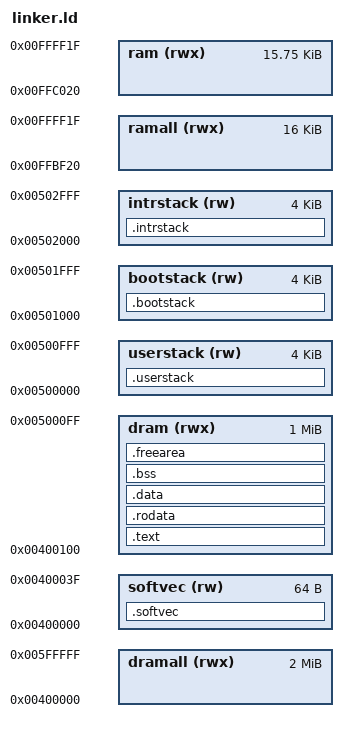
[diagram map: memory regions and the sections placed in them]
/* OUTPUT_FORMAT("elf32-h8300") */
OUTPUT_ARCH(h8300h)
ENTRY("_start")

/*********************************************************************************
	CPUアドレスサイズ 16MB
	割り込みベクタ	0x000000 -> 0x0000FF (256 Bytes)
	内蔵ROM			0x000100 -> 0x07FFFF (512 KB)
	Reserve			0x080000 -> 0xFFBF1F ( )
	内蔵RAM			0xFFBF20 -> 0xFFFF1F (16 KB)
	内蔵I/Oレジスタ	0xFFFF20 -> 0xFFFFE9 (208 bytes)
	Reserve			0xFFFFF0 -> 0xFFFFFF

	PA = Physical Address	物理アドレス
	VA = Vitual Address		論理アドレス

（１）リセット処理 ベクタ番号0 H'0000〜H'0003
RES端子がLowで発生。事実上最も優先順位が高い例外処理です。

（２）トラップ処理 ベクタ番号8〜11
命令語の中に TRAPA という命令が有り、複数のプログラムがあたかも同時に処理されている様な動きを見せます。マルチタスキングシステムでは必須の機能です。ソフトウエア割込とも呼ばれています。４個のTRAPAがあり、レベルを持たせたソフトウエア割込が実現できます。

（３）外部割込 NMI（ノンマスカラブルインタラプト） ベクタ番号７ マスク（阻止）できない外部割込です。
（４）外部割込 IRQ（インタラプトリクエスト） ベクタ番号12〜17 プログラムによってマスク（阻止）したり解除できる割込です。

（５）内部割込 ベクタ番号20〜60 IRQと似ていますが、発生事象がH8チップ内に内蔵する専用機能から発生するものです。その詳細はデーターシートをお読み下さい。

*********************************************************************************/

/*********************************************************************************
	各メモリ領域の定義
**********************************************************************************/
MEMORY
{
	/******************************************************************************
		コロンの前は、定義するメモリ領域の名称。
		ORIGINは、定義するメモリ領域の先頭アドレス。
		LENGTHは、定義するメモリ領域のサイズ。
		カッコ内のrwxはもちろん、読み、書き、実行の可否。
	******************************************************************************/
	/* 「o」はORIGIN、「l」はLENGTH */
	/* ELFヘッダのためにDRAMの先頭256バイト予約 */
	dramall(rwx)	: o = 0x400000, l = 0x200000	/* DRAM領域全体(2MB) */
	dram(rwx)		: o = 0x400100, l = 0x100000
	ramall(rwx)		: o = 0xFFBF20, l = 0x004000	/* RAM領域全体(16KB) */
	softvec(rw)		: o = 0x400000, l = 0x000040
	ram(rwx)		: o = 0xFFC020, l = 0x003F00
	userstack(rw)	: o = 0x500000, l = 0x001000
	bootstack(rw)	: o = 0x501000, l = 0x001000	/* スタック領域 RAMの末尾 */
	intrstack(rw)	: o = 0x502000, l = 0x001000	/* スタック領域 RAMの末尾 */
}

/**********************************************************************************
	各セクションの定義
**********************************************************************************/
SECTIONS
{
	. = ALIGN(4);
	/*****************************************************************************
	 * tbd
	******************************************************************************/
	.softvec : {
		_softvec = . ;	/* vectorsの直後の領域のアドレスを変数に格納しておく */
	} > softvec /* RAM領域に配置する */

	/******************************************************************************
		テキスト領域
	CPUが実行する機械語コードが配置される。
	リンカによって各オブジェクトファイルの.textセクションの内容が集められる。
	*******************************************************************************/
	.text : {
		_text_top = . ;	/* vectorsの直後の領域のアドレスを変数に格納しておく */
		*(.text)
		_text_btm = . ;		/* テキスト領域の終端も同様 */
	} > dram /*ram*/ /* RAM領域に配置する */

	/******************************************************************************
		読み込み専用領域(Read Only Data)
	const定義や文字列リテラルなどが配置される。
	*******************************************************************************/
	.rodata : {
		_rodata_top = . ;
		*(.strings)
		*(.rodata)
		*(.rodata.*)
		_rodata_btm = . ;
	} > dram /*ram*/ /* RAM領域に配置する */

	/******************************************************************************
		データ領域
	初期値を持つ静的変数が配置される。
		"> data AT > rom"
	"> data"により、RAM領域上へリンクが行われるように設定される。
	よって、「実行コード」は"data"のアドレス範囲内の変数に対して読み書きをする。

	"AT > rom"により、dataセクションはROM領域へロードされる。
	*******************************************************************************/
	/* データ領域 */
	/* 初期値を持つ静的変数などが配置される */
	.data : {
		_data_top = . ;
		*(.data)
		_data_btm = . ;
	} > dram /*ram*/ /* RAM領域に配置する */

	/******************************************************************************
		BSS領域
	初期値を持たない静的変数が配置される。
	つまり、変数のサイズの情報が配置される。
	*******************************************************************************/
	/* BSS領域 */
	/* 初期値を持たない静的変数などが配置される */
	.bss : {
		_bss_top = . ;
	*(.bss)
	*(COMMON)
		_bss_btm = . ;
	} > dram /*ram*/


	. = ALIGN(4);
	_end = . ;

	.freearea : {
		_freearea = .;
	} > dram

	.userstack : {
		_userstack = . ;
	} > userstack

	.bootstack : {
		_bootstack = . ;
	} > bootstack

	.intrstack : {
		_intrstack = . ;
	} > intrstack
}



